# STM32H7P5 register map
File version: 2.0.0
CPU: CM7 r1p2, little endian, MPU, FPU, 4 interrupt priority bits
Registers are 32-bit, read-write, reset 0x0 unless marked. A register's access mark holds for its fields unless they carry their own. Offsets are from the block's base; [hi:lo] are bit positions; {n}, {i} and the like mark numbered series.

## GPIOA — GPIO address block description
Base 0x58020000
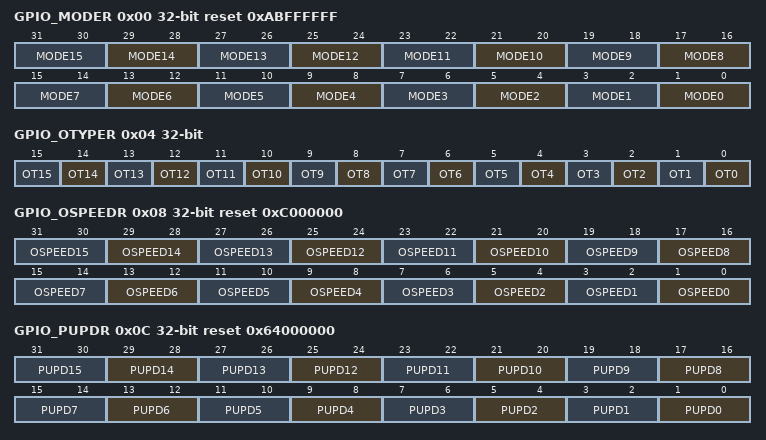
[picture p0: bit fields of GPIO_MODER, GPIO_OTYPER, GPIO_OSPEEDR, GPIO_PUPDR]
0x00 GPIO_MODER reset 0xABFFFFFF — GPIO port mode register
  [all] fields
    0=Input mode; 1=General purpose output mode; 2=Alternate function mode; 3=Analog mode (reset state)
  [2n+1:2n] MODE{n} (n=0..15) — Port x configuration I/O pin y
0x04 GPIO_OTYPER — GPIO port output type register
  [all] fields
    0=Output push-pull (reset state); 1=Output open-drain
  [n] OT{n} (n=0..15) — Port x configuration I/O pin y
0x08 GPIO_OSPEEDR reset 0xC000000 — GPIO port output speed register
  [all] fields
    0=Low speed; 1=Medium speed; 2=High speed; 3=Very-high speed
  [2n+1:2n] OSPEED{n} (n=0..15) — Port x configuration I/O pin y
0x0C GPIO_PUPDR reset 0x64000000 — GPIO port pull-up/pull-down register
  [all] fields
    0=No pull-up, pull-down; 1=Pull-up; 2=Pull-down
  [2n+1:2n] PUPD{n} (n=0..15) — Port x configuration I/O pin y
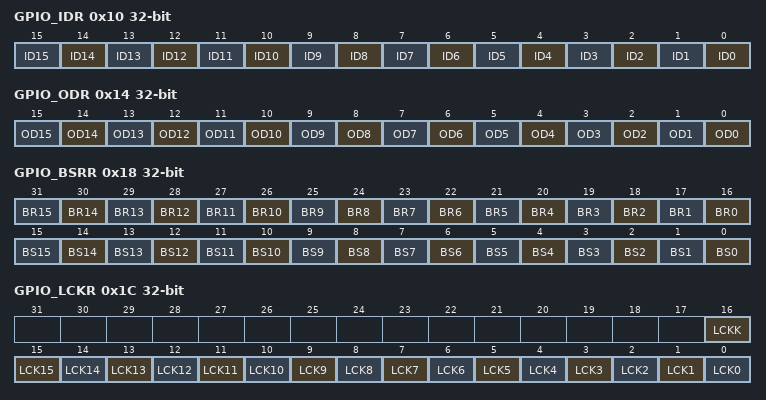
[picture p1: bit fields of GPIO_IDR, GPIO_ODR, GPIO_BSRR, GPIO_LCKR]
0x10 GPIO_IDR ro — GPIO port input data register
  [n] ID{n} (n=0..15) — Port x input data I/O pin y
0x14 GPIO_ODR — GPIO port output data register
  [n] OD{n} (n=0..15) — Port output data I/O pin y
0x18 GPIO_BSRR wo — GPIO port bit set/reset register
  [n+16] BR{n} (n=0..15) — Port x reset I/O pin y
    0=No action on the corresponding ODy bit; 1=Resets the corresponding ODy bit
  [n] BS{n} (n=0..15) — Port x set I/O pin y
    0=No action on the corresponding ODy bit; 1=Sets the corresponding ODy bit
0x1C GPIO_LCKR — GPIO port configuration lock register
  [16] LCKK — Lock key
    0=Port configuration lock key not active; 1=Port configuration lock key active. The GPIOx_LCKR register is locked until the next MCU reset or peripheral reset.
  [n] LCK{n} (n=0..15) — Port x lock I/O pin y
    0=Port configuration not locked; 1=Port configuration locked
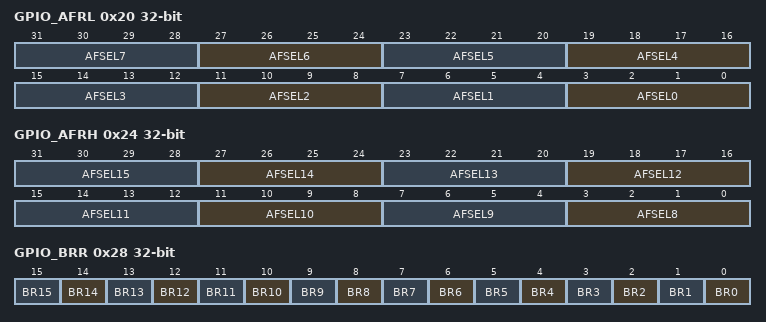
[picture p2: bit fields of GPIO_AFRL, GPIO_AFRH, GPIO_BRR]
0x20 GPIO_AFRL — GPIO alternate function low register
  [all] fields
    {v}=AF{v} (v=0..15)
  [4n+3:4n] AFSEL{n} (n=0..7) — Alternate function selection for port x I/O pin y
0x24 GPIO_AFRH — GPIO alternate function high register
  [all] fields
    {v}=AF{v} (v=0..15)
  [4n-29:4n-32] AFSEL{n} (n=8..15) — Alternate function selection for port x I/O pin y
0x28 GPIO_BRR wo — GPIO port bit reset register
  [all] fields
    0=No action on the corresponding ODy bit; 1=Reset the corresponding ODy bit
  [n] BR{n} (n=0..15) — Port x reset IO pin y

## GPIOB — GPIO address block description
Base 0x58020400
Registers as GPIOA; these are added or differ:
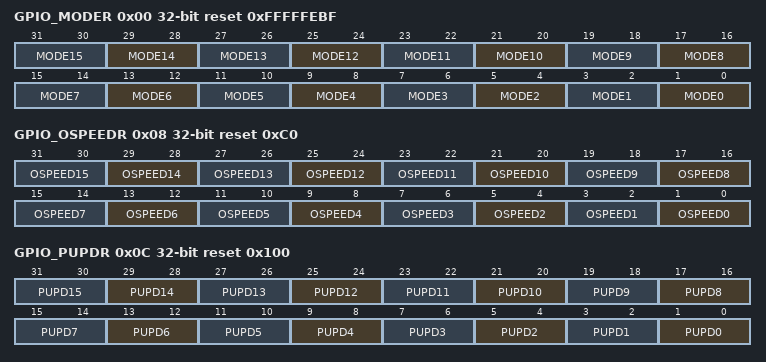
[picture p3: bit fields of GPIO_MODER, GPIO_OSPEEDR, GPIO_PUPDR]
0x00 GPIO_MODER reset 0xFFFFFEBF — GPIO port mode register
  [all] fields
    0=Input mode; 1=General purpose output mode; 2=Alternate function mode; 3=Analog mode (reset state)
  [2n+1:2n] MODE{n} (n=0..15) — Port x configuration I/O pin y
0x08 GPIO_OSPEEDR reset 0xC0 — GPIO port output speed register
  [all] fields
    0=Low speed; 1=Medium speed; 2=High speed; 3=Very-high speed
  [2n+1:2n] OSPEED{n} (n=0..15) — Port x configuration I/O pin y
0x0C GPIO_PUPDR reset 0x100 — GPIO port pull-up/pull-down register
  [all] fields
    0=No pull-up, pull-down; 1=Pull-up; 2=Pull-down
  [2n+1:2n] PUPD{n} (n=0..15) — Port x configuration I/O pin y

## GPIOC — GPIO address block description
Base 0x58020800
Same registers: GPIOD 0x58020C00, GPIOE 0x58021000, GPIOF 0x58021400, GPIOG 0x58021800, GPIOH 0x58021C00
Registers as GPIOA; these are added or differ:
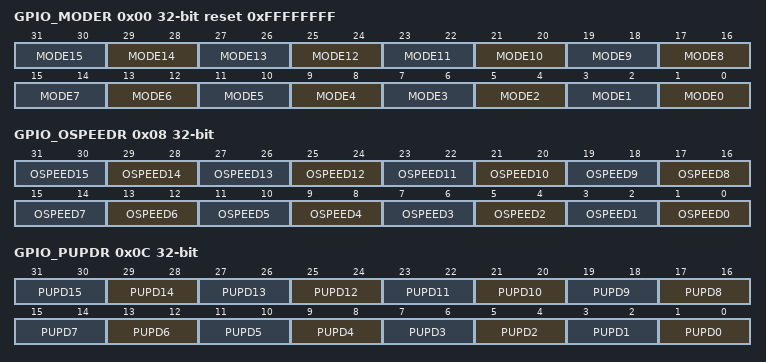
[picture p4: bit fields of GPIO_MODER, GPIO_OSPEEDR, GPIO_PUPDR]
0x00 GPIO_MODER reset 0xFFFFFFFF — GPIO port mode register
  [all] fields
    0=Input mode; 1=General purpose output mode; 2=Alternate function mode; 3=Analog mode (reset state)
  [2n+1:2n] MODE{n} (n=0..15) — Port x configuration I/O pin y
0x08 GPIO_OSPEEDR — GPIO port output speed register
  [all] fields
    0=Low speed; 1=Medium speed; 2=High speed; 3=Very-high speed
  [2n+1:2n] OSPEED{n} (n=0..15) — Port x configuration I/O pin y
0x0C GPIO_PUPDR — GPIO port pull-up/pull-down register
  [all] fields
    0=No pull-up, pull-down; 1=Pull-up; 2=Pull-down
  [2n+1:2n] PUPD{n} (n=0..15) — Port x configuration I/O pin y

## GPIOI — GPIO address block description
Base 0x58022000
Registers as GPIOC; these are added or differ:
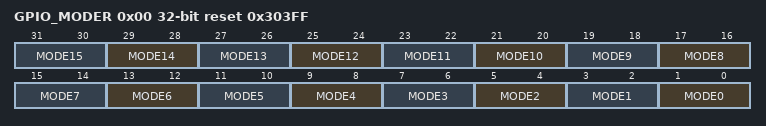
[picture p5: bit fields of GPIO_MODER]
0x00 GPIO_MODER reset 0x303FF — GPIO port mode register
  [all] fields
    0=Input mode; 1=General purpose output mode; 2=Alternate function mode; 3=Analog mode (reset state)
  [2n+1:2n] MODE{n} (n=0..15) — Port x configuration I/O pin y
